# TM4C129ENCPDT register map
File version: 1.0
CPU: CORTEX_M4 1.0, other endian, MPU, FPU, 3 interrupt priority bits
Registers are 32-bit, read-write, reset 0x0 unless marked. A register's access mark holds for its fields unless they carry their own. Offsets are from the block's base; [hi:lo] are bit positions; {n}, {i} and the like mark numbered series; 'fields as' and 'values as' point back to an identical list.

## EPI0 — External Peripheral Interface register offsets
Base 0x400D0000
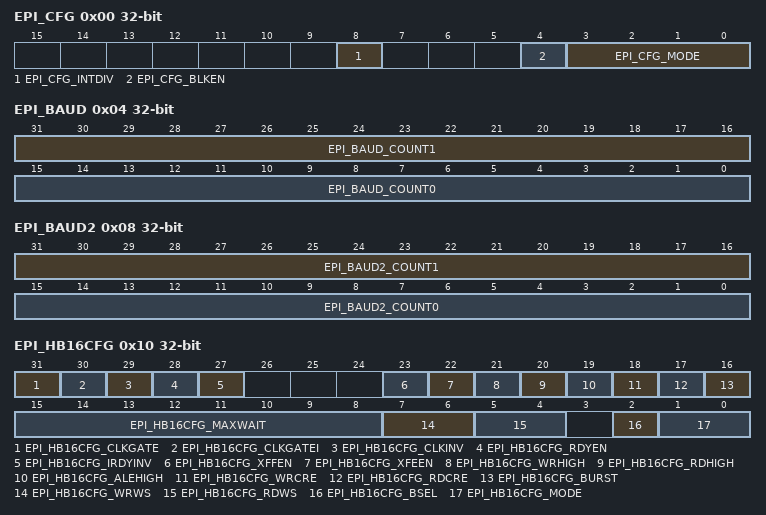
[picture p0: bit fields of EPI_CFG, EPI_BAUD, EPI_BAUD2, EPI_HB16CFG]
0x00 EPI_CFG — EPI Configuration
  [8] EPI_CFG_INTDIV — [8:8] Integer Clock Divider Enable
  [4] EPI_CFG_BLKEN — [4:4] Block Enable
  [3:0] EPI_CFG_MODE — [3:0] Mode Select
    0=EPI_CFG_MODE_NONE (General Purpose); 1=EPI_CFG_MODE_SDRAM (SDRAM); 2=EPI_CFG_MODE_HB8 (8-Bit Host-Bus (HB8)); 3=EPI_CFG_MODE_HB16 (16-Bit Host-Bus (HB16))
0x04 EPI_BAUD — EPI Main Baud Rate
  [31:16] EPI_BAUD_COUNT1 — [31:16] Baud Rate Counter 1
  [15:0] EPI_BAUD_COUNT0 — [15:0] Baud Rate Counter 0
0x08 EPI_BAUD2 — EPI Main Baud Rate
  [31:16] EPI_BAUD2_COUNT1 — [31:16] CS3n Baud Rate Counter 1
  [15:0] EPI_BAUD2_COUNT0 — [15:0] CS2n Baud Rate Counter 0
0x10 EPI_HB16CFG — EPI Host-Bus 16 Configuration
  [31] EPI_HB16CFG_CLKGATE — [31:31] Clock Gated
  [30] EPI_HB16CFG_CLKGATEI — [30:30] Clock Gated Idle
  [29] EPI_HB16CFG_CLKINV — [29:29] Invert Output Clock Enable
  [28] EPI_HB16CFG_RDYEN — [28:28] Input Ready Enable
  [27] EPI_HB16CFG_IRDYINV — [27:27] Input Ready Invert
  [23] EPI_HB16CFG_XFFEN — [23:23] External FIFO FULL Enable
  [22] EPI_HB16CFG_XFEEN — [22:22] External FIFO EMPTY Enable
  [21] EPI_HB16CFG_WRHIGH — [21:21] WRITE Strobe Polarity
  [20] EPI_HB16CFG_RDHIGH — [20:20] READ Strobe Polarity
  [19] EPI_HB16CFG_ALEHIGH — [19:19] ALE Strobe Polarity
  [18] EPI_HB16CFG_WRCRE — [18:18] PSRAM Configuration Register Write
  [17] EPI_HB16CFG_RDCRE — [17:17] PSRAM Configuration Register Read
  [16] EPI_HB16CFG_BURST — [16:16] Burst Mode
  [15:8] EPI_HB16CFG_MAXWAIT — [15:8] Maximum Wait
  [7:6] EPI_HB16CFG_WRWS — [7:6] Write Wait States
    0=Active WRn is 2 EPI clocks; 64=Active WRn is 4 EPI clocks; 128=Active WRn is 6 EPI clocks; 192=Active WRn is 8 EPI clocks
  [5:4] EPI_HB16CFG_RDWS — [5:4] Read Wait States
    0=Active RDn is 2 EPI clocks; 16=Active RDn is 4 EPI clocks; 32=Active RDn is 6 EPI clocks; 48=Active RDn is 8 EPI clocks
  [2] EPI_HB16CFG_BSEL — [2:2] Byte Select Configuration
  [1:0] EPI_HB16CFG_MODE — [1:0] Host Bus Sub-Mode
    0=EPI_HB16CFG_MODE_ADMUX (ADMUX - AD[15:0]); 1=EPI_HB16CFG_MODE_ADNMUX (ADNONMUX - D[15:0]); 2=EPI_HB16CFG_MODE_SRAM (Continuous Read - D[15:0]); 3=EPI_HB16CFG_MODE_XFIFO (XFIFO - D[15:0])
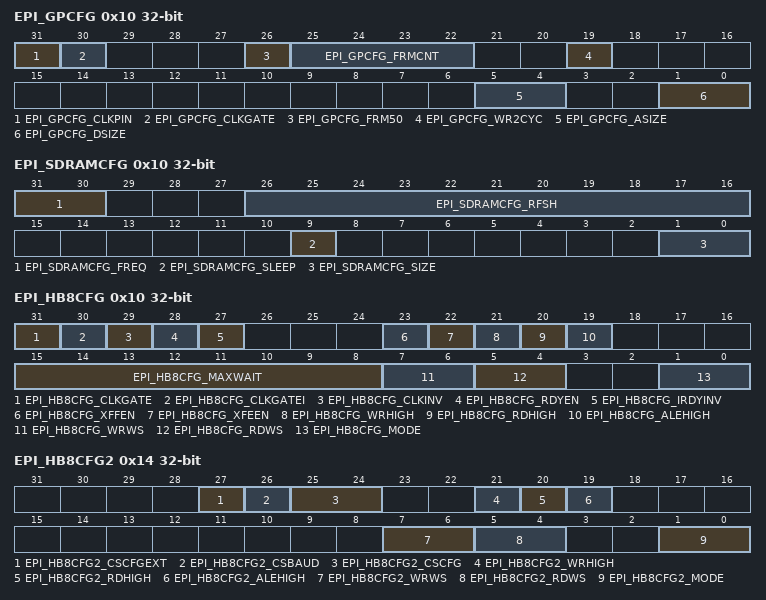
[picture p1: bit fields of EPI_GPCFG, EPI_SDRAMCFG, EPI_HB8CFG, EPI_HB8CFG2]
0x10 EPI_GPCFG — EPI General-Purpose Configuration
  [31] EPI_GPCFG_CLKPIN — [31:31] Clock Pin
  [30] EPI_GPCFG_CLKGATE — [30:30] Clock Gated
  [26] EPI_GPCFG_FRM50 — [26:26] 50/50 Frame
  [25:22] EPI_GPCFG_FRMCNT — [25:22] Frame Count
  [19] EPI_GPCFG_WR2CYC — [19:19] 2-Cycle Writes
  [5:4] EPI_GPCFG_ASIZE — [5:4] Address Bus Size
    0=EPI_GPCFG_ASIZE_NONE (No address); 16=EPI_GPCFG_ASIZE_4BIT (Up to 4 bits wide); 32=EPI_GPCFG_ASIZE_12BIT (Up to 12 bits wide. This size cannot be used with 24-bit data); 48=EPI_GPCFG_ASIZE_20BIT (Up to 20 bits wide. This size cannot be used with data sizes other than 8)
  [1:0] EPI_GPCFG_DSIZE — [1:0] Size of Data Bus
    0=EPI_GPCFG_DSIZE_4BIT (8 Bits Wide (EPI0S0 to EPI0S7)); 1=EPI_GPCFG_DSIZE_16BIT (16 Bits Wide (EPI0S0 to EPI0S15)); 2=EPI_GPCFG_DSIZE_24BIT (24 Bits Wide (EPI0S0 to EPI0S23)); 3=EPI_GPCFG_DSIZE_32BIT (32 Bits Wide (EPI0S0 to EPI0S31))
0x10 EPI_SDRAMCFG — EPI SDRAM Configuration
  [31:30] EPI_SDRAMCFG_FREQ — [31:30] EPI Frequency Range
    0=EPI_SDRAMCFG_FREQ_NONE (0 - 15 MHz); 0x40000000=EPI_SDRAMCFG_FREQ_15MHZ (15 - 30 MHz); 0x80000000=EPI_SDRAMCFG_FREQ_30MHZ (30 - 50 MHz)
  [26:16] EPI_SDRAMCFG_RFSH — [26:16] Refresh Counter
  [9] EPI_SDRAMCFG_SLEEP — [9:9] Sleep Mode
  [1:0] EPI_SDRAMCFG_SIZE — [1:0] Size of SDRAM
    0=EPI_SDRAMCFG_SIZE_8MB (64 megabits (8MB)); 1=EPI_SDRAMCFG_SIZE_16MB (128 megabits (16MB)); 2=EPI_SDRAMCFG_SIZE_32MB (256 megabits (32MB)); 3=EPI_SDRAMCFG_SIZE_64MB (512 megabits (64MB))
0x10 EPI_HB8CFG — EPI Host-Bus 8 Configuration
  [31] EPI_HB8CFG_CLKGATE — [31:31] Clock Gated
  [30] EPI_HB8CFG_CLKGATEI — [30:30] Clock Gated when Idle
  [29] EPI_HB8CFG_CLKINV — [29:29] Invert Output Clock Enable
  [28] EPI_HB8CFG_RDYEN — [28:28] Input Ready Enable
  [27] EPI_HB8CFG_IRDYINV — [27:27] Input Ready Invert
  [23] EPI_HB8CFG_XFFEN — [23:23] External FIFO FULL Enable
  [22] EPI_HB8CFG_XFEEN — [22:22] External FIFO EMPTY Enable
  [21] EPI_HB8CFG_WRHIGH — [21:21] WRITE Strobe Polarity
  [20] EPI_HB8CFG_RDHIGH — [20:20] READ Strobe Polarity
  [19] EPI_HB8CFG_ALEHIGH — [19:19] ALE Strobe Polarity
  [15:8] EPI_HB8CFG_MAXWAIT — [15:8] Maximum Wait
  [7:6] EPI_HB8CFG_WRWS — [7:6] Write Wait States
    values as EPI_HB16CFG.EPI_HB16CFG_WRWS
  [5:4] EPI_HB8CFG_RDWS — [5:4] Read Wait States
    values as EPI_HB16CFG.EPI_HB16CFG_RDWS
  [1:0] EPI_HB8CFG_MODE — [1:0] Host Bus Sub-Mode
    0=EPI_HB8CFG_MODE_MUX (ADMUX - AD[7:0]); 1=EPI_HB8CFG_MODE_NMUX (ADNONMUX - D[7:0]); 2=EPI_HB8CFG_MODE_SRAM (Continuous Read - D[7:0]); 3=EPI_HB8CFG_MODE_FIFO (XFIFO - D[7:0])
0x14 EPI_HB8CFG2 — EPI Host-Bus 8 Configuration 2
  [27] EPI_HB8CFG2_CSCFGEXT — [27:27] Chip Select Extended Configuration
  [26] EPI_HB8CFG2_CSBAUD — [26:26] Chip Select Baud Rate and Multiple Sub-Mode Configuration enable
  [25:24] EPI_HB8CFG2_CSCFG — [25:24] Chip Select Configuration
    0=EPI_HB8CFG2_CSCFG_ALE (ALE Configuration); 0x1000000=EPI_HB8CFG2_CSCFG_CS (CSn Configuration); 0x2000000=EPI_HB8CFG2_CSCFG_DCS (Dual CSn Configuration); 0x3000000=EPI_HB8CFG2_CSCFG_ADCS (ALE with Dual CSn Configuration)
  [21] EPI_HB8CFG2_WRHIGH — [21:21] CS1n WRITE Strobe Polarity
  [20] EPI_HB8CFG2_RDHIGH — [20:20] CS1n READ Strobe Polarity
  [19] EPI_HB8CFG2_ALEHIGH — [19:19] CS1n ALE Strobe Polarity
  [7:6] EPI_HB8CFG2_WRWS — [7:6] CS1n Write Wait States
    values as EPI_HB16CFG.EPI_HB16CFG_WRWS
  [5:4] EPI_HB8CFG2_RDWS — [5:4] CS1n Read Wait States
    values as EPI_HB16CFG.EPI_HB16CFG_RDWS
  [1:0] EPI_HB8CFG2_MODE — [1:0] CS1n Host Bus Sub-Mode
    0=EPI_HB8CFG2_MODE_ADMUX (ADMUX - AD[7:0]); 1=EPI_HB8CFG2_MODE_AD (ADNONMUX - D[7:0])
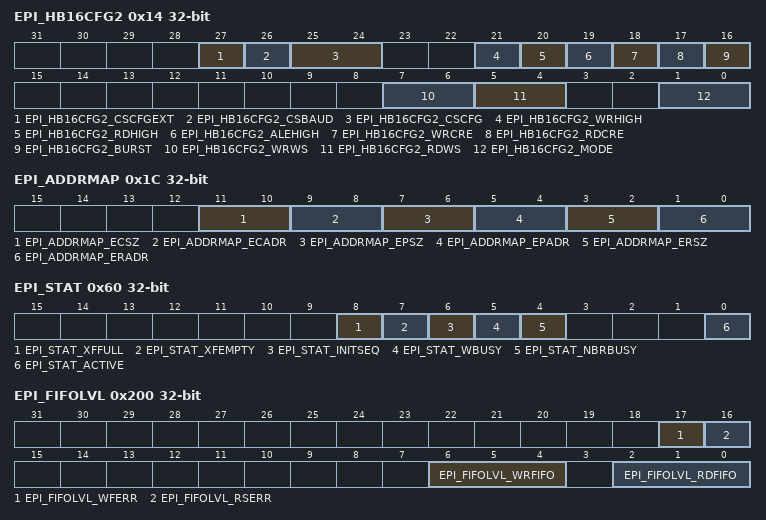
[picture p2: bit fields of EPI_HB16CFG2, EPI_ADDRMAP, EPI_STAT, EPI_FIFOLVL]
0x14 EPI_HB16CFG2 — EPI Host-Bus 16 Configuration 2
  [27] EPI_HB16CFG2_CSCFGEXT — [27:27] Chip Select Extended Configuration
  [26] EPI_HB16CFG2_CSBAUD — [26:26] Chip Select Baud Rate and Multiple Sub-Mode Configuration enable
  [25:24] EPI_HB16CFG2_CSCFG — [25:24] Chip Select Configuration
    0=EPI_HB16CFG2_CSCFG_ALE (ALE Configuration); 0x1000000=EPI_HB16CFG2_CSCFG_CS (CSn Configuration); 0x2000000=EPI_HB16CFG2_CSCFG_DCS (Dual CSn Configuration); 0x3000000=EPI_HB16CFG2_CSCFG_ADCS (ALE with Dual CSn Configuration)
  [21] EPI_HB16CFG2_WRHIGH — [21:21] CS1n WRITE Strobe Polarity
  [20] EPI_HB16CFG2_RDHIGH — [20:20] CS1n READ Strobe Polarity
  [19] EPI_HB16CFG2_ALEHIGH — [19:19] CS1n ALE Strobe Polarity
  [18] EPI_HB16CFG2_WRCRE — [18:18] CS1n PSRAM Configuration Register Write
  [17] EPI_HB16CFG2_RDCRE — [17:17] CS1n PSRAM Configuration Register Read
  [16] EPI_HB16CFG2_BURST — [16:16] CS1n Burst Mode
  [7:6] EPI_HB16CFG2_WRWS — [7:6] CS1n Write Wait States
    values as EPI_HB16CFG.EPI_HB16CFG_WRWS
  [5:4] EPI_HB16CFG2_RDWS — [5:4] CS1n Read Wait States
    values as EPI_HB16CFG.EPI_HB16CFG_RDWS
  [1:0] EPI_HB16CFG2_MODE — [1:0] CS1n Host Bus Sub-Mode
    0=EPI_HB16CFG2_MODE_ADMUX (ADMUX - AD[15:0]); 1=EPI_HB16CFG2_MODE_AD (ADNONMUX - D[15:0])
0x1C EPI_ADDRMAP — EPI Address Map
  [11:10] EPI_ADDRMAP_ECSZ — [11:10] External Code Size
    0=EPI_ADDRMAP_ECSZ_256B (256 bytes; lower address range: 0x00 to 0xFF); 0x400=EPI_ADDRMAP_ECSZ_64KB (64 KB; lower address range: 0x0000 to 0xFFFF); 0x800=EPI_ADDRMAP_ECSZ_16MB (16 MB; lower address range: 0x00.0000 to 0xFF.FFFF); 0xC00=EPI_ADDRMAP_ECSZ_256MB (256MB; lower address range: 0x000.0000 to 0x0FFF.FFFF)
  [9:8] EPI_ADDRMAP_ECADR — [9:8] External Code Address
    0=EPI_ADDRMAP_ECADR_NONE (Not mapped); 0x100=At 0x1000.0000
  [7:6] EPI_ADDRMAP_EPSZ — [7:6] External Peripheral Size
    0=EPI_ADDRMAP_EPSZ_256B (256 bytes; lower address range: 0x00 to 0xFF); 64=EPI_ADDRMAP_EPSZ_64KB (64 KB; lower address range: 0x0000 to 0xFFFF); 128=EPI_ADDRMAP_EPSZ_16MB (16 MB; lower address range: 0x00.0000 to 0xFF.FFFF); 192=EPI_ADDRMAP_EPSZ_256MB (256 MB; lower address range: 0x000.0000 to 0xFFF.FFFF)
  [5:4] EPI_ADDRMAP_EPADR — [5:4] External Peripheral Address
    0=EPI_ADDRMAP_EPADR_NONE (Not mapped); 16=EPI_ADDRMAP_EPADR_A000 (At 0xA000.0000); 32=EPI_ADDRMAP_EPADR_C000 (At 0xC000.0000); 48=EPI_ADDRMAP_EPADR_HBQS (Only to be used with Host Bus quad chip select. In quad chip select mode, CS2n maps to 0xA000.0000 and CS3n maps to 0xC000.0000)
  [3:2] EPI_ADDRMAP_ERSZ — [3:2] External RAM Size
    0=EPI_ADDRMAP_ERSZ_256B (256 bytes; lower address range: 0x00 to 0xFF); 4=EPI_ADDRMAP_ERSZ_64KB (64 KB; lower address range: 0x0000 to 0xFFFF); 8=EPI_ADDRMAP_ERSZ_16MB (16 MB; lower address range: 0x00.0000 to 0xFF.FFFF); 12=EPI_ADDRMAP_ERSZ_256MB (256 MB; lower address range: 0x000.0000 to 0xFFF.FFFF)
  [1:0] EPI_ADDRMAP_ERADR — [1:0] External RAM Address
    0=EPI_ADDRMAP_ERADR_NONE (Not mapped); 1=At 0x6000.0000; 2=At 0x8000.0000; 3=EPI_ADDRMAP_ERADR_HBQS (Only to be used with Host Bus quad chip select. In quad chip select mode, CS0n maps to 0x6000.0000 and CS1n maps to 0x8000.0000)
0x20 EPI_RSIZE0 — EPI Read Size 0
  [1:0] EPI_RSIZE0_SIZE — [1:0] Current Size
    1=EPI_RSIZE0_SIZE_8BIT (Byte (8 bits)); 2=EPI_RSIZE0_SIZE_16BIT (Half-word (16 bits)); 3=EPI_RSIZE0_SIZE_32BIT (Word (32 bits))
0x24 EPI_RADDR0 — EPI Read Address 0
  [31:0] EPI_RADDR0_ADDR — [31:0] Current Address
0x28 EPI_RPSTD0 — EPI Non-Blocking Read Data 0
  [12:0] EPI_RPSTD0_POSTCNT — [12:0] Post Count
0x30 EPI_RSIZE1 — EPI Read Size 1
  [1:0] EPI_RSIZE1_SIZE — [1:0] Current Size
    1=EPI_RSIZE1_SIZE_8BIT (Byte (8 bits)); 2=EPI_RSIZE1_SIZE_16BIT (Half-word (16 bits)); 3=EPI_RSIZE1_SIZE_32BIT (Word (32 bits))
0x34 EPI_RADDR1 — EPI Read Address 1
  [31:0] EPI_RADDR1_ADDR — [31:0] Current Address
0x38 EPI_RPSTD1 — EPI Non-Blocking Read Data 1
  [12:0] EPI_RPSTD1_POSTCNT — [12:0] Post Count
0x60 EPI_STAT — EPI Status
  [8] EPI_STAT_XFFULL — [8:8] External FIFO Full
  [7] EPI_STAT_XFEMPTY — [7:7] External FIFO Empty
  [6] EPI_STAT_INITSEQ — [6:6] Initialization Sequence
  [5] EPI_STAT_WBUSY — [5:5] Write Busy
  [4] EPI_STAT_NBRBUSY — [4:4] Non-Blocking Read Busy
  [0] EPI_STAT_ACTIVE — [0:0] Register Active
0x6C EPI_RFIFOCNT — EPI Read FIFO Count
  [3:0] EPI_RFIFOCNT_COUNT — [3:0] FIFO Count
0x70 EPI_READFIFO0 — EPI Read FIFO
  [31:0] EPI_READFIFO0_DATA — [31:0] Reads Data
{0x70+4i} EPI_READFIFO{i} (i=1..7) — EPI Read FIFO Alias {i}
  [31:0] EPI_READFIFO{i}_DATA — [31:0] Reads Data
0x200 EPI_FIFOLVL — EPI FIFO Level Selects
  [17] EPI_FIFOLVL_WFERR — [17:17] Write Full Error
  [16] EPI_FIFOLVL_RSERR — [16:16] Read Stall Error
  [6:4] EPI_FIFOLVL_WRFIFO — [6:4] Write FIFO
    0=EPI_FIFOLVL_WRFIFO_EMPT (Interrupt is triggered while WRFIFO is empty.); 32=Interrupt is triggered until there are only two slots available. Thus, trigger is deasserted when there are two WRFIFO entries present. This configuration is optimized for bursts of 2; 48=Interrupt is triggered until there is one WRFIFO entry available. This configuration expects only single writes; 64=EPI_FIFOLVL_WRFIFO_NFULL (Trigger interrupt when WRFIFO is not full, meaning trigger will continue to assert until there are four entries in the WRFIFO)
  [2:0] EPI_FIFOLVL_RDFIFO — [2:0] Read FIFO
    1=Trigger when there are 1 or more entries in the NBRFIFO; 2=Trigger when there are 2 or more entries in the NBRFIFO; 3=Trigger when there are 4 or more entries in the NBRFIFO; 4=Trigger when there are 6 or more entries in the NBRFIFO; 5=Trigger when there are 7 or more entries in the NBRFIFO; 6=Trigger when there are 8 entries in the NBRFIFO
0x204 EPI_WFIFOCNT — EPI Write FIFO Count
  [2:0] EPI_WFIFOCNT_WTAV — [2:0] Available Write Transactions
0x208 EPI_DMATXCNT — EPI DMA Transmit Count
  [15:0] EPI_DMATXCNT_TXCNT — [15:0] DMA Count
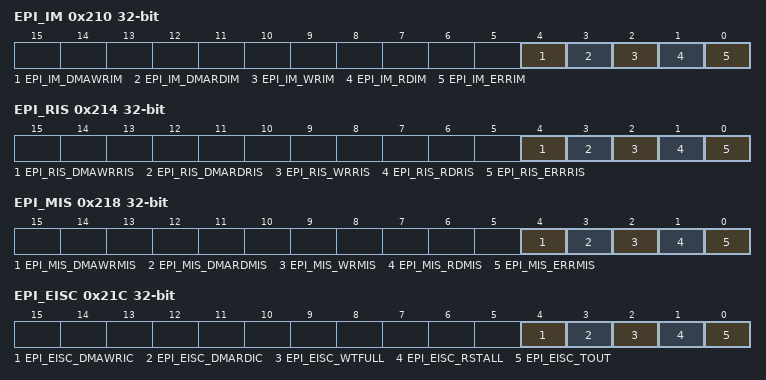
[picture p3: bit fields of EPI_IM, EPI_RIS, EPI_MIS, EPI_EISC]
0x210 EPI_IM — EPI Interrupt Mask
  [4] EPI_IM_DMAWRIM — [4:4] Write uDMA Interrupt Mask
  [3] EPI_IM_DMARDIM — [3:3] Read uDMA Interrupt Mask
  [2] EPI_IM_WRIM — [2:2] Write FIFO Empty Interrupt Mask
  [1] EPI_IM_RDIM — [1:1] Read FIFO Full Interrupt Mask
  [0] EPI_IM_ERRIM — [0:0] Error Interrupt Mask
0x214 EPI_RIS — EPI Raw Interrupt Status
  [4] EPI_RIS_DMAWRRIS — [4:4] Write uDMA Raw Interrupt Status
  [3] EPI_RIS_DMARDRIS — [3:3] Read uDMA Raw Interrupt Status
  [2] EPI_RIS_WRRIS — [2:2] Write Raw Interrupt Status
  [1] EPI_RIS_RDRIS — [1:1] Read Raw Interrupt Status
  [0] EPI_RIS_ERRRIS — [0:0] Error Raw Interrupt Status
0x218 EPI_MIS — EPI Masked Interrupt Status
  [4] EPI_MIS_DMAWRMIS — [4:4] Write uDMA Masked Interrupt Status
  [3] EPI_MIS_DMARDMIS — [3:3] Read uDMA Masked Interrupt Status
  [2] EPI_MIS_WRMIS — [2:2] Write Masked Interrupt Status
  [1] EPI_MIS_RDMIS — [1:1] Read Masked Interrupt Status
  [0] EPI_MIS_ERRMIS — [0:0] Error Masked Interrupt Status
0x21C EPI_EISC — EPI Error and Interrupt Status and Clear
  [4] EPI_EISC_DMAWRIC — [4:4] Write uDMA Interrupt Clear
  [3] EPI_EISC_DMARDIC — [3:3] Read uDMA Interrupt Clear
  [2] EPI_EISC_WTFULL — [2:2] Write FIFO Full Error
  [1] EPI_EISC_RSTALL — [1:1] Read Stalled Error
  [0] EPI_EISC_TOUT — [0:0] Timeout Error
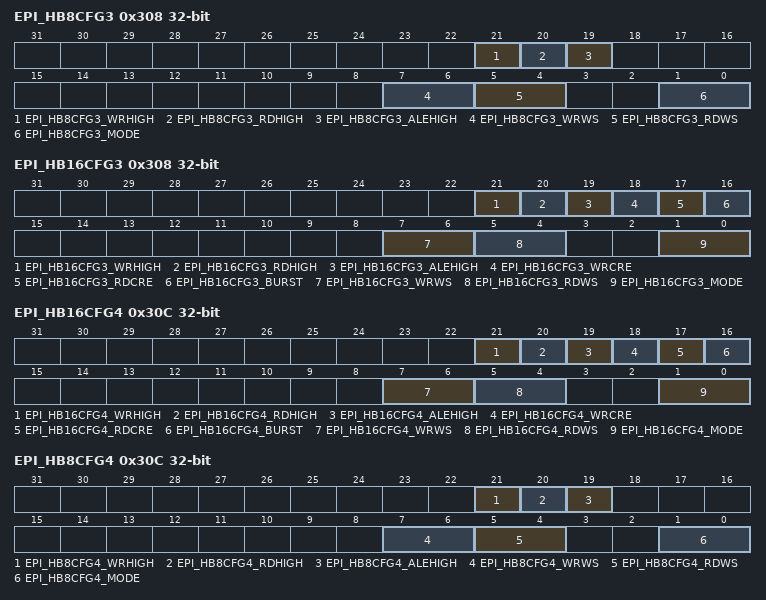
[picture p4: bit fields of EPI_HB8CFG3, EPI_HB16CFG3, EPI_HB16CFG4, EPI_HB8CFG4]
0x308 EPI_HB8CFG3 — EPI Host-Bus 8 Configuration 3
  [21] EPI_HB8CFG3_WRHIGH — [21:21] CS2n WRITE Strobe Polarity
  [20] EPI_HB8CFG3_RDHIGH — [20:20] CS2n READ Strobe Polarity
  [19] EPI_HB8CFG3_ALEHIGH — [19:19] CS2n ALE Strobe Polarity
  [7:6] EPI_HB8CFG3_WRWS — [7:6] CS2n Write Wait States
    values as EPI_HB16CFG.EPI_HB16CFG_WRWS
  [5:4] EPI_HB8CFG3_RDWS — [5:4] CS2n Read Wait States
    values as EPI_HB16CFG.EPI_HB16CFG_RDWS
  [1:0] EPI_HB8CFG3_MODE — [1:0] CS2n Host Bus Sub-Mode
    0=EPI_HB8CFG3_MODE_ADMUX (ADMUX - AD[7:0]); 1=EPI_HB8CFG3_MODE_AD (ADNONMUX - D[7:0])
0x308 EPI_HB16CFG3 — EPI Host-Bus 16 Configuration 3
  [21] EPI_HB16CFG3_WRHIGH — [21:21] CS2n WRITE Strobe Polarity
  [20] EPI_HB16CFG3_RDHIGH — [20:20] CS2n READ Strobe Polarity
  [19] EPI_HB16CFG3_ALEHIGH — [19:19] CS2n ALE Strobe Polarity
  [18] EPI_HB16CFG3_WRCRE — [18:18] CS2n PSRAM Configuration Register Write
  [17] EPI_HB16CFG3_RDCRE — [17:17] CS2n PSRAM Configuration Register Read
  [16] EPI_HB16CFG3_BURST — [16:16] CS2n Burst Mode
  [7:6] EPI_HB16CFG3_WRWS — [7:6] CS2n Write Wait States
    values as EPI_HB16CFG.EPI_HB16CFG_WRWS
  [5:4] EPI_HB16CFG3_RDWS — [5:4] CS2n Read Wait States
    values as EPI_HB16CFG.EPI_HB16CFG_RDWS
  [1:0] EPI_HB16CFG3_MODE — [1:0] CS2n Host Bus Sub-Mode
    0=EPI_HB16CFG3_MODE_ADMUX (ADMUX - AD[15:0]); 1=EPI_HB16CFG3_MODE_AD (ADNONMUX - D[15:0])
0x30C EPI_HB16CFG4 — EPI Host-Bus 16 Configuration 4
  [21] EPI_HB16CFG4_WRHIGH — [21:21] CS3n WRITE Strobe Polarity
  [20] EPI_HB16CFG4_RDHIGH — [20:20] CS3n READ Strobe Polarity
  [19] EPI_HB16CFG4_ALEHIGH — [19:19] CS3n ALE Strobe Polarity
  [18] EPI_HB16CFG4_WRCRE — [18:18] CS3n PSRAM Configuration Register Write
  [17] EPI_HB16CFG4_RDCRE — [17:17] CS3n PSRAM Configuration Register Read
  [16] EPI_HB16CFG4_BURST — [16:16] CS3n Burst Mode
  [7:6] EPI_HB16CFG4_WRWS — [7:6] CS3n Write Wait States
    values as EPI_HB16CFG.EPI_HB16CFG_WRWS
  [5:4] EPI_HB16CFG4_RDWS — [5:4] CS3n Read Wait States
    values as EPI_HB16CFG.EPI_HB16CFG_RDWS
  [1:0] EPI_HB16CFG4_MODE — [1:0] CS3n Host Bus Sub-Mode
    0=EPI_HB16CFG4_MODE_ADMUX (ADMUX - AD[15:0]); 1=EPI_HB16CFG4_MODE_AD (ADNONMUX - D[15:0])
0x30C EPI_HB8CFG4 — EPI Host-Bus 8 Configuration 4
  [21] EPI_HB8CFG4_WRHIGH — [21:21] CS3n WRITE Strobe Polarity
  [20] EPI_HB8CFG4_RDHIGH — [20:20] CS2n READ Strobe Polarity
  [19] EPI_HB8CFG4_ALEHIGH — [19:19] CS3n ALE Strobe Polarity
  [7:6] EPI_HB8CFG4_WRWS — [7:6] CS3n Write Wait States
    values as EPI_HB16CFG.EPI_HB16CFG_WRWS
  [5:4] EPI_HB8CFG4_RDWS — [5:4] CS3n Read Wait States
    values as EPI_HB16CFG.EPI_HB16CFG_RDWS
  [1:0] EPI_HB8CFG4_MODE — [1:0] CS3n Host Bus Sub-Mode
    0=EPI_HB8CFG4_MODE_ADMUX (ADMUX - AD[7:0]); 1=EPI_HB8CFG4_MODE_AD (ADNONMUX - D[7:0])
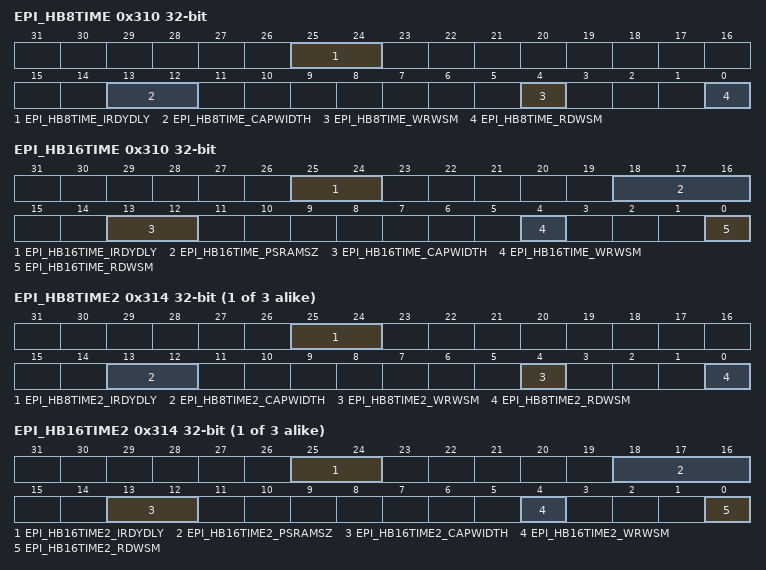
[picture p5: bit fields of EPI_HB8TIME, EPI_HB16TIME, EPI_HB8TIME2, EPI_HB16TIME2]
0x310 EPI_HB8TIME — EPI Host-Bus 8 Timing Extension
  [25:24] EPI_HB8TIME_IRDYDLY — [25:24] CS0n Input Ready Delay
  [13:12] EPI_HB8TIME_CAPWIDTH — [13:12] CS0n Inter-transfer Capture Width
  [4] EPI_HB8TIME_WRWSM — [4:4] Write Wait State Minus One
  [0] EPI_HB8TIME_RDWSM — [0:0] Read Wait State Minus One
0x310 EPI_HB16TIME — EPI Host-Bus 16 Timing Extension
  [25:24] EPI_HB16TIME_IRDYDLY — [25:24] CS0n Input Ready Delay
  [18:16] EPI_HB16TIME_PSRAMSZ — [18:16] PSRAM Row Size
    0=No row size limitation; 0x10000=EPI_HB16TIME_PSRAMSZ_128B (128 B); 0x20000=EPI_HB16TIME_PSRAMSZ_256B (256 B); 0x30000=EPI_HB16TIME_PSRAMSZ_512B (512 B); 0x40000=EPI_HB16TIME_PSRAMSZ_1KB (1024 B); 0x50000=EPI_HB16TIME_PSRAMSZ_2KB (2048 B); 0x60000=EPI_HB16TIME_PSRAMSZ_4KB (4096 B); 0x70000=EPI_HB16TIME_PSRAMSZ_8KB (8192 B)
  [13:12] EPI_HB16TIME_CAPWIDTH — [13:12] CS0n Inter-transfer Capture Width
  [4] EPI_HB16TIME_WRWSM — [4:4] Write Wait State Minus One
  [0] EPI_HB16TIME_RDWSM — [0:0] Read Wait State Minus One
{0x30C+4i} EPI_HB8TIME{i} (i=2..4) — EPI Host-Bus 8 Timing Extension
  [25:24] EPI_HB8TIME{i}_IRDYDLY — [25:24] CS{i-1}n Input Ready Delay
  [13:12] EPI_HB8TIME{i}_CAPWIDTH — [13:12] CS{i-1}n Inter-transfer Capture Width
  [4] EPI_HB8TIME{i}_WRWSM — [4:4] CS{i-1}n Write Wait State Minus One
  [0] EPI_HB8TIME{i}_RDWSM — [0:0] CS{i-1}n Read Wait State Minus One
{0x30C+4i} EPI_HB16TIME{i} (i=2..4) — EPI Host-Bus 16 Timing Extension
  [25:24] EPI_HB16TIME{i}_IRDYDLY — [25:24] CS{i-1}n Input Ready Delay
  [18:16] EPI_HB16TIME{i}_PSRAMSZ — [18:16] PSRAM Row Size
    0=No row size limitation; 0x10000=EPI_HB16TIME{i}_PSRAMSZ_128B (128 B); 0x20000=EPI_HB16TIME{i}_PSRAMSZ_256B (256 B); 0x30000=EPI_HB16TIME{i}_PSRAMSZ_512B (512 B); 0x40000=EPI_HB16TIME{i}_PSRAMSZ_1KB (1024 B); 0x50000=EPI_HB16TIME{i}_PSRAMSZ_2KB (2048 B); 0x60000=EPI_HB16TIME{i}_PSRAMSZ_4KB (4096 B); 0x70000=EPI_HB16TIME{i}_PSRAMSZ_8KB (8192 B)
  [13:12] EPI_HB16TIME{i}_CAPWIDTH — [13:12] CS{i-1}n Inter-transfer Capture Width
  [4] EPI_HB16TIME{i}_WRWSM — [4:4] CS{i-1}n Write Wait State Minus One
  [0] EPI_HB16TIME{i}_RDWSM — [0:0] CS{i-1}n Read Wait State Minus One
0x360 EPI_HBPSRAM — EPI Host-Bus PSRAM
  [20:0] EPI_HBPSRAM_CR — [20:0] PSRAM Config Register
